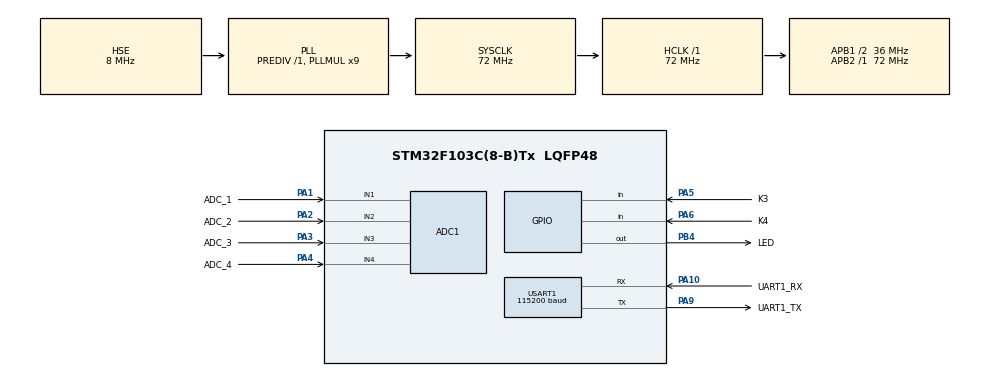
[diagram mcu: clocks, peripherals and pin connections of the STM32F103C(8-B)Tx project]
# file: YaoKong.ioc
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ADC1.Channel-0\#ChannelRegularConversion=ADC_CHANNEL_1
ADC1.Channel-1\#ChannelRegularConversion=ADC_CHANNEL_4
ADC1.Channel-2\#ChannelRegularConversion=ADC_CHANNEL_2
ADC1.Channel-3\#ChannelRegularConversion=ADC_CHANNEL_3
ADC1.ContinuousConvMode=DISABLE
ADC1.DataAlign=ADC_DATAALIGN_RIGHT
ADC1.DiscontinuousConvMode=DISABLE
ADC1.EnableAnalogWatchDog=false
ADC1.EnableRegularConversion=ENABLE
ADC1.ExternalTrigConv=ADC_SOFTWARE_START
ADC1.ExternalTrigConvEdgeChoice=RISING
ADC1.InjNumberOfConversion=0
ADC1.NbrOfConversion=4
ADC1.NbrOfConversionFlag=1
ADC1.Rank-0\#ChannelRegularConversion=1
ADC1.Rank-1\#ChannelRegularConversion=2
ADC1.Rank-2\#ChannelRegularConversion=3
ADC1.Rank-3\#ChannelRegularConversion=4
ADC1.SamplingTime-0\#ChannelRegularConversion=ADC_SAMPLETIME_1CYCLE_5
ADC1.SamplingTime-1\#ChannelRegularConversion=ADC_SAMPLETIME_1CYCLE_5
ADC1.SamplingTime-2\#ChannelRegularConversion=ADC_SAMPLETIME_1CYCLE_5
ADC1.SamplingTime-3\#ChannelRegularConversion=ADC_SAMPLETIME_1CYCLE_5
ADC1.ScanConvMode=ADC_SCAN_ENABLE
ADC1.master=1
Dma.ADC1.0.Direction=DMA_PERIPH_TO_MEMORY
Dma.ADC1.0.Instance=DMA1_Channel1
Dma.ADC1.0.MemDataAlignment=DMA_MDATAALIGN_WORD
Dma.ADC1.0.MemInc=DMA_MINC_ENABLE
Dma.ADC1.0.Mode=DMA_CIRCULAR
Dma.ADC1.0.PeriphDataAlignment=DMA_PDATAALIGN_WORD
Dma.ADC1.0.PeriphInc=DMA_PINC_DISABLE
Dma.ADC1.0.Priority=DMA_PRIORITY_HIGH
Dma.Request0=ADC1
FREERTOS.BinarySemaphores01=g_BinarySemUart
FREERTOS.INCLUDE_vTaskDelayUntil=1
FREERTOS.Queues01=g_QueueToUart,4,uint32_t,NULL
FREERTOS.Tasks01=TaskUartTx,0,128,StartTaskUartTx
FREERTOS.Timers01=TimerLed,Callback_Led,osTimerPeriodic;TimerAdc,Callback_Adc,osTimerPeriodic;TimerKey,Callback_Key,osTimerPeriodic
FREERTOS.configMINIMAL_STACK_SIZE=64
FREERTOS.configTOTAL_HEAP_SIZE=10240
FREERTOS.configUSE_IDLE_HOOK=1
FREERTOS.configUSE_TICK_HOOK=1
FREERTOS.configUSE_TIMERS=1
Mcu.Family=STM32F1
Mcu.Name=STM32F103C(8-B)Tx
Mcu.Package=LQFP48
NVIC.DMA1_Channel1_IRQn=true\:5\:0\:false
NVIC.PriorityGroup=NVIC_PRIORITYGROUP_4
PA1.GPIO_Label=ADC_1
PA1.Signal=ADCx_IN1
PA10.GPIO_Label=UART1_RX
PA10.Mode=Asynchronous
PA10.Signal=USART1_RX
PA13.Mode=Serial_Wire
PA13.Signal=SYS_JTMS-SWDIO
PA14.Mode=Serial_Wire
PA14.Signal=SYS_JTCK-SWCLK
PA2.GPIO_Label=ADC_2
PA2.Signal=ADCx_IN2
PA3.GPIO_Label=ADC_3
PA3.Signal=ADCx_IN3
PA4.GPIO_Label=ADC_4
PA4.Signal=ADCx_IN4
PA5.GPIO_Label=K3
PA5.Signal=GPIO_Input
PA6.GPIO_Label=K4
PA6.Signal=GPIO_Input
PA9.GPIO_Label=UART1_TX
PA9.Mode=Asynchronous
PA9.Signal=USART1_TX
PB4.GPIO_Label=LED
PB4.GPIO_Speed=GPIO_SPEED_HIGH
PB4.Signal=GPIO_Output
PD0-OSC_IN.Mode=HSE-External-Oscillator
PD0-OSC_IN.Signal=RCC_OSC_IN
PD1-OSC_OUT.Mode=HSE-External-Oscillator
PD1-OSC_OUT.Signal=RCC_OSC_OUT
ProjectManager.TargetToolchain=MDK-ARM V5
RCC.ADCPresc=RCC_ADCPCLK2_DIV6
RCC.AHBFreq_Value=72000000
RCC.APB1CLKDivider=RCC_HCLK_DIV2
RCC.APB1Freq_Value=36000000
RCC.APB1TimFreq_Value=72000000
RCC.APB2Freq_Value=72000000
RCC.APB2TimFreq_Value=72000000
RCC.HCLKFreq_Value=72000000
RCC.HSIState=RCC_HSI_ON
RCC.PLLMUL=RCC_PLL_MUL9
RCC.PLLSourceVirtual=RCC_PLLSOURCE_HSE
RCC.SYSCLKFreq_VALUE=72000000
RCC.SYSCLKSource=RCC_SYSCLKSOURCE_PLLCLK
RCC.USBFreq_Value=72000000
SH.ADCx_IN1.0=ADC1_IN1,IN1
SH.ADCx_IN2.0=ADC1_IN2,IN2
SH.ADCx_IN3.0=ADC1_IN3,IN3
SH.ADCx_IN4.0=ADC1_IN4,IN4
USART1.BaudRate=115200
VP_FREERTOS_VS_ENABLE.Mode=Enabled
board=YaoKong

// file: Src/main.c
/**
  ******************************************************************************
  * File Name          : main.c
  * Description        : Main program body
  ******************************************************************************
  *
  * COPYRIGHT(c) 2016 STMicroelectronics
  *
  * Redistribution and use in source and binary forms, with or without modification,
  * are permitted provided that the following conditions are met:
  *   1. Redistributions of source code must retain the above copyright notice,
  *      this list of conditions and the following disclaimer.
  *   2. Redistributions in binary form must reproduce the above copyright notice,
  *      this list of conditions and the following disclaimer in the documentation
  *      and/or other materials provided with the distribution.
  *   3. Neither the name of STMicroelectronics nor the names of its contributors
  *      may be used to endorse or promote products derived from this software
  *      without specific prior written permission.
  *
  * THIS SOFTWARE IS PROVIDED BY THE COPYRIGHT HOLDERS AND CONTRIBUTORS "AS IS"
  * AND ANY EXPRESS OR IMPLIED WARRANTIES, INCLUDING, BUT NOT LIMITED TO, THE
  * IMPLIED WARRANTIES OF MERCHANTABILITY AND FITNESS FOR A PARTICULAR PURPOSE ARE
  * DISCLAIMED. IN NO EVENT SHALL THE COPYRIGHT HOLDER OR CONTRIBUTORS BE LIABLE
  * FOR ANY DIRECT, INDIRECT, INCIDENTAL, SPECIAL, EXEMPLARY, OR CONSEQUENTIAL
  * DAMAGES (INCLUDING, BUT NOT LIMITED TO, PROCUREMENT OF SUBSTITUTE GOODS OR
  * SERVICES; LOSS OF USE, DATA, OR PROFITS; OR BUSINESS INTERRUPTION) HOWEVER
  * CAUSED AND ON ANY THEORY OF LIABILITY, WHETHER IN CONTRACT, STRICT LIABILITY,
  * OR TORT (INCLUDING NEGLIGENCE OR OTHERWISE) ARISING IN ANY WAY OUT OF THE USE
  * OF THIS SOFTWARE, EVEN IF ADVISED OF THE POSSIBILITY OF SUCH DAMAGE.
  *
  ******************************************************************************
  */
#include "stm32f1xx_hal.h"
#include "cmsis_os.h"

/* USER CODE BEGIN Includes */
#include "SEGGER_RTT_Conf.h"
#include "SEGGER_RTT.h"
#include "CMSIS_OS_SUPPLEMENT.h"
#include "Bsp.h"
/* USER CODE END Includes */

ADC_HandleTypeDef hadc1;
DMA_HandleTypeDef hdma_adc1;

UART_HandleTypeDef huart1;

osThreadId TaskUartTxHandle;
osMessageQId g_QueueToUartHandle;
osTimerId TimerLedHandle;
osTimerId TimerAdcHandle;
osTimerId TimerKeyHandle;
osSemaphoreId g_BinarySemUartHandle;

/* USER CODE BEGIN PV */
/* Private variables ---------------------------------------------------------*/
osSemaphoreId g_CountingSemUartHandle;
/* USER CODE END PV */

void SystemClock_Config(void);
static void MX_GPIO_Init(void);
static void MX_DMA_Init(void);
static void MX_ADC1_Init(void);
static void MX_USART1_UART_Init(void);
void StartTaskUartTx(void const * argument);
void Callback_Led(void const * argument);
void Callback_Adc(void const * argument);
void Callback_Key(void const * argument);

/* USER CODE BEGIN PFP */
/* Private function prototypes -----------------------------------------------*/

/* USER CODE END PFP */

/* USER CODE BEGIN 0 */
void CallBackUartTxToPC(void);
/* USER CODE END 0 */

int main(void)
{

  /* MCU Configuration----------------------------------------------------------*/

  /* Reset of all peripherals, Initializes the Flash interface and the Systick. */
  HAL_Init();

  /* Configure the system clock */
  SystemClock_Config();

  /* Initialize all configured peripherals */
  MX_GPIO_Init();
  MX_DMA_Init();
  MX_ADC1_Init();
  MX_USART1_UART_Init();

  /* USER CODE BEGIN 2 */
  BspInit();
  /* USER CODE END 2 */

  /* Create the semaphores(s) */
  /* definition and creation of g_BinarySemUart */
  osSemaphoreDef(g_BinarySemUart);
  g_BinarySemUartHandle = osSemaphoreCreate(osSemaphore(g_BinarySemUart), 1);

  /* USER CODE BEGIN RTOS_SEMAPHORES */
  /* add semaphores, ... */
  osSemaphoreDef(g_CountingSemUart);
  g_CountingSemUartHandle = osUserDefinedSemaphoreCreate(osSemaphore(g_CountingSemUart), UART_QUEUE_SIZE);
  /* USER CODE END RTOS_SEMAPHORES */

  /* Create the timer(s) */
  /* definition and creation of TimerLed */
  osTimerDef(TimerLed, Callback_Led);
  TimerLedHandle = osTimerCreate(osTimer(TimerLed), osTimerPeriodic, NULL);

  /* definition and creation of TimerAdc */
  osTimerDef(TimerAdc, Callback_Adc);
  TimerAdcHandle = osTimerCreate(osTimer(TimerAdc), osTimerPeriodic, NULL);

  /* definition and creation of TimerKey */
  osTimerDef(TimerKey, Callback_Key);
  TimerKeyHandle = osTimerCreate(osTimer(TimerKey), osTimerPeriodic, NULL);

  /* USER CODE BEGIN RTOS_TIMERS */
 // osTimerStart(TimerKeyHandle,10);
  osTimerStart(TimerAdcHandle,100);
 // osTimerStart(TimerLedHandle,500);
  /* start timers, add new ones, ... */
  /* USER CODE END RTOS_TIMERS */

  /* Create the thread(s) */
  /* definition and creation of TaskUartTx */
  osThreadDef(TaskUartTx, StartTaskUartTx, osPriorityNormal, 0, 128);
  TaskUartTxHandle = osThreadCreate(osThread(TaskUartTx), NULL);

  /* Create the queue(s) */
  /* definition and creation of g_QueueToUart */
  osMessageQDef(g_QueueToUart, 4, uint32_t);
  g_QueueToUartHandle = osMessageCreate(osMessageQ(g_QueueToUart), NULL);

  /* Start scheduler */
  osKernelStart();

  /* We should never get here as control is now taken by the scheduler */

  /* Infinite loop */
  while (1)
  {

  }

}

/** System Clock Configuration
*/
void SystemClock_Config(void)
{

  RCC_OscInitTypeDef RCC_OscInitStruct;
  RCC_ClkInitTypeDef RCC_ClkInitStruct;
  RCC_PeriphCLKInitTypeDef PeriphClkInit;

  RCC_OscInitStruct.OscillatorType = RCC_OSCILLATORTYPE_HSE;
  RCC_OscInitStruct.HSEState = RCC_HSE_ON;
  RCC_OscInitStruct.HSEPredivValue = RCC_HSE_PREDIV_DIV1;
  RCC_OscInitStruct.PLL.PLLState = RCC_PLL_ON;
  RCC_OscInitStruct.PLL.PLLSource = RCC_PLLSOURCE_HSE;
  RCC_OscInitStruct.PLL.PLLMUL = RCC_PLL_MUL9;
  HAL_RCC_OscConfig(&RCC_OscInitStruct);

  RCC_ClkInitStruct.ClockType = RCC_CLOCKTYPE_SYSCLK|RCC_CLOCKTYPE_PCLK1;
  RCC_ClkInitStruct.SYSCLKSource = RCC_SYSCLKSOURCE_PLLCLK;
  RCC_ClkInitStruct.AHBCLKDivider = RCC_SYSCLK_DIV1;
  RCC_ClkInitStruct.APB1CLKDivider = RCC_HCLK_DIV2;
  RCC_ClkInitStruct.APB2CLKDivider = RCC_HCLK_DIV1;
  HAL_RCC_ClockConfig(&RCC_ClkInitStruct, FLASH_LATENCY_2);

  PeriphClkInit.PeriphClockSelection = RCC_PERIPHCLK_ADC;
  PeriphClkInit.AdcClockSelection = RCC_ADCPCLK2_DIV6;
  HAL_RCCEx_PeriphCLKConfig(&PeriphClkInit);

  HAL_SYSTICK_Config(HAL_RCC_GetHCLKFreq()/1000);

  HAL_SYSTICK_CLKSourceConfig(SYSTICK_CLKSOURCE_HCLK);

  /* SysTick_IRQn interrupt configuration */
  HAL_NVIC_SetPriority(SysTick_IRQn, 15, 0);
}

/* ADC1 init function */
void MX_ADC1_Init(void)
{

  ADC_ChannelConfTypeDef sConfig;

    /**Common config
    */
  hadc1.Instance = ADC1;
  hadc1.Init.ScanConvMode = ADC_SCAN_ENABLE;
  hadc1.Init.ContinuousConvMode = DISABLE;
  hadc1.Init.DiscontinuousConvMode = DISABLE;
  hadc1.Init.ExternalTrigConv = ADC_SOFTWARE_START;
  hadc1.Init.DataAlign = ADC_DATAALIGN_RIGHT;
  hadc1.Init.NbrOfConversion = 4;
  HAL_ADC_Init(&hadc1);

    /**Configure Regular Channel
    */
  sConfig.Channel = ADC_CHANNEL_1;
  sConfig.Rank = 1;
  sConfig.SamplingTime = ADC_SAMPLETIME_1CYCLE_5;
  HAL_ADC_ConfigChannel(&hadc1, &sConfig);

    /**Configure Regular Channel
    */
  sConfig.Channel = ADC_CHANNEL_4;
  sConfig.Rank = 2;
  HAL_ADC_ConfigChannel(&hadc1, &sConfig);

    /**Configure Regular Channel
    */
  sConfig.Channel = ADC_CHANNEL_2;
  sConfig.Rank = 3;
  HAL_ADC_ConfigChannel(&hadc1, &sConfig);

    /**Configure Regular Channel
    */
  sConfig.Channel = ADC_CHANNEL_3;
  sConfig.Rank = 4;
  HAL_ADC_ConfigChannel(&hadc1, &sConfig);

}

/* USART1 init function */
void MX_USART1_UART_Init(void)
{

  huart1.Instance = USART1;
  huart1.Init.BaudRate = 115200;
  huart1.Init.WordLength = UART_WORDLENGTH_8B;
  huart1.Init.StopBits = UART_STOPBITS_1;
  huart1.Init.Parity = UART_PARITY_NONE;
  huart1.Init.Mode = UART_MODE_TX_RX;
  huart1.Init.HwFlowCtl = UART_HWCONTROL_NONE;
  huart1.Init.OverSampling = UART_OVERSAMPLING_16;
  HAL_UART_Init(&huart1);

}

void MX_DMA_Init(void)
{
  /* DMA controller clock enable */
  __HAL_RCC_DMA1_CLK_ENABLE();

  /* DMA interrupt init */
  HAL_NVIC_SetPriority(DMA1_Channel1_IRQn, 5, 0);
  HAL_NVIC_EnableIRQ(DMA1_Channel1_IRQn);

}

/** Configure pins as
        * Analog
        * Input
        * Output
        * EVENT_OUT
        * EXTI
*/
void MX_GPIO_Init(void)
{

  GPIO_InitTypeDef GPIO_InitStruct;

  /* GPIO Ports Clock Enable */
  __GPIOD_CLK_ENABLE();
  __GPIOA_CLK_ENABLE();
  __GPIOB_CLK_ENABLE();

  /*Configure GPIO pins : K3_Pin K4_Pin */
  GPIO_InitStruct.Pin = K3_Pin|K4_Pin;
  GPIO_InitStruct.Mode = GPIO_MODE_INPUT;
  GPIO_InitStruct.Pull = GPIO_NOPULL;
  HAL_GPIO_Init(GPIOA, &GPIO_InitStruct);

  /*Configure GPIO pin : LED_Pin */
  GPIO_InitStruct.Pin = LED_Pin;
  GPIO_InitStruct.Mode = GPIO_MODE_OUTPUT_PP;
  GPIO_InitStruct.Speed = GPIO_SPEED_HIGH;
  HAL_GPIO_Init(LED_GPIO_Port, &GPIO_InitStruct);

}

/* StartTaskUartTx function */
void StartTaskUartTx(void const * argument)
{

  /* USER CODE BEGIN 5 */
  /* Infinite loop */
  CallBackUartTxToPC();
  //osDelay(1000);
  /* USER CODE END 5 */
}

/* Callback_Led function */
void Callback_Led(void const * argument)
{
  /* USER CODE BEGIN Callback_Led */
  //LedPro();
  /* USER CODE END Callback_Led */
}

/* Callback_Adc function */
void Callback_Adc(void const * argument)
{
  /* USER CODE BEGIN Callback_Adc */
  //AdcPro();
  /* USER CODE END Callback_Adc */
}

/* Callback_Key function */
void Callback_Key(void const * argument)
{
  /* USER CODE BEGIN Callback_Key */
  KeyPro();
  /* USER CODE END Callback_Key */
}

/************************ (C) COPYRIGHT STMicroelectronics *****END OF FILE****/

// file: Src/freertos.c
/**
  ******************************************************************************
  * File Name          : freertos.c
  * Description        : Code for freertos applications
  ******************************************************************************
  *
  * COPYRIGHT(c) 2016 STMicroelectronics
  *
  * Redistribution and use in source and binary forms, with or without modification,
  * are permitted provided that the following conditions are met:
  *   1. Redistributions of source code must retain the above copyright notice,
  *      this list of conditions and the following disclaimer.
  *   2. Redistributions in binary form must reproduce the above copyright notice,
  *      this list of conditions and the following disclaimer in the documentation
  *      and/or other materials provided with the distribution.
  *   3. Neither the name of STMicroelectronics nor the names of its contributors
  *      may be used to endorse or promote products derived from this software
  *      without specific prior written permission.
  *
  * THIS SOFTWARE IS PROVIDED BY THE COPYRIGHT HOLDERS AND CONTRIBUTORS "AS IS"
  * AND ANY EXPRESS OR IMPLIED WARRANTIES, INCLUDING, BUT NOT LIMITED TO, THE
  * IMPLIED WARRANTIES OF MERCHANTABILITY AND FITNESS FOR A PARTICULAR PURPOSE ARE
  * DISCLAIMED. IN NO EVENT SHALL THE COPYRIGHT HOLDER OR CONTRIBUTORS BE LIABLE
  * FOR ANY DIRECT, INDIRECT, INCIDENTAL, SPECIAL, EXEMPLARY, OR CONSEQUENTIAL
  * DAMAGES (INCLUDING, BUT NOT LIMITED TO, PROCUREMENT OF SUBSTITUTE GOODS OR
  * SERVICES; LOSS OF USE, DATA, OR PROFITS; OR BUSINESS INTERRUPTION) HOWEVER
  * CAUSED AND ON ANY THEORY OF LIABILITY, WHETHER IN CONTRACT, STRICT LIABILITY,
  * OR TORT (INCLUDING NEGLIGENCE OR OTHERWISE) ARISING IN ANY WAY OUT OF THE USE
  * OF THIS SOFTWARE, EVEN IF ADVISED OF THE POSSIBILITY OF SUCH DAMAGE.
  *
  ******************************************************************************
  */

#include "FreeRTOS.h"
#include "task.h"

/* USER CODE BEGIN Includes */
#include "HalCallBack.h"
/* USER CODE END Includes */

/* Hook prototypes */
void vApplicationIdleHook(void);
void vApplicationTickHook(void);

/* USER CODE BEGIN 2 */
void vApplicationIdleHook( void )
{
   /* vApplicationIdleHook() will only be called if configUSE_IDLE_HOOK is set
   to 1 in FreeRTOSConfig.h. It will be called on each iteration of the idle
   task. It is essential that code added to this hook function never attempts
   to block in any way (for example, call xQueueReceive() with a block time
   specified, or call vTaskDelay()). If the application makes use of the
   vTaskDelete() API function (as this demo application does) then it is also
   important that vApplicationIdleHook() is permitted to return to its calling
   function, because it is the responsibility of the idle task to clean up
   memory allocated by the kernel to any task that has since been deleted. */
}
/* USER CODE END 2 */

/* USER CODE BEGIN 3 */
void vApplicationTickHook( void )
{
   /* This function will be called by each tick interrupt if
   configUSE_TICK_HOOK is set to 1 in FreeRTOSConfig.h. User code can be
   added here, but the tick hook is called from an interrupt context, so
   code must not attempt to block, and only the interrupt safe FreeRTOS API
   functions can be used (those that end in FromISR()). */
   // CallBackTick();
}
/* USER CODE END 3 */

/************************ (C) COPYRIGHT STMicroelectronics *****END OF FILE****/
